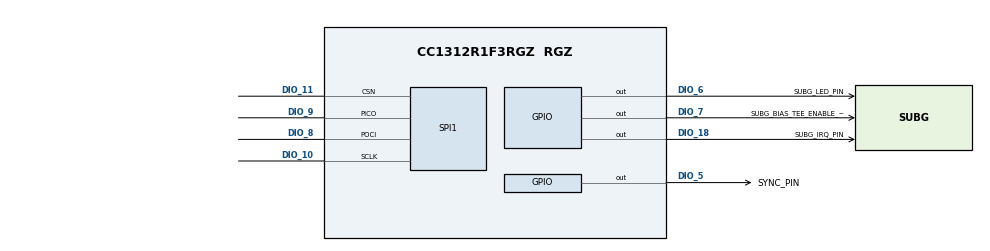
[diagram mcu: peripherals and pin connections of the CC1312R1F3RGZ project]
/**
 * @cliArgs --device "CC1312R1F3RGZ" --part "Default" --package "RGZ" --rtos "freertos" --product "simplelink_cc13xx_cc26xx_sdk@8.30.01.01"
 * @versions {"tool":"1.23.1+4034"}
 */

/**
 * Import the modules used in this configuration.
 */
const CCFG     = scripting.addModule("/ti/devices/CCFG");
const custom   = scripting.addModule("/ti/devices/radioconfig/custom");
const rfdesign = scripting.addModule("/ti/devices/radioconfig/rfdesign");
const Board    = scripting.addModule("/ti/drivers/Board");
const DMA      = scripting.addModule("/ti/drivers/DMA");
const GPIO     = scripting.addModule("/ti/drivers/GPIO");
const GPIO1    = GPIO.addInstance();
const GPIO2    = GPIO.addInstance();
const GPIO3    = GPIO.addInstance();
const GPIO4    = GPIO.addInstance();
const RF       = scripting.addModule("/ti/drivers/RF");
const SPI      = scripting.addModule("/ti/drivers/SPI", {}, false);
const SPI1     = SPI.addInstance();

/**
 * Write custom configuration values to the imported modules.
 */
CCFG.enableBootloader         = true;
CCFG.enableBootloaderBackdoor = true;
CCFG.dioBootloaderBackdoor    = 5;
CCFG.xoscCapArray             = true;
// -3 steps: CC1312 crystal on the RP2040's. ti_devices_config.c also enables the linear delta by hand.
CCFG.xoscCapArrayDelta        = 0xFD;
CCFG.ccfgTemplate.$name       = "ti_devices_CCFG_CCFGCC26XXTemplate0";

custom.prop8                                       = ["custom868"];
custom.radioConfigcustom868.$name                  = "ti_devices_radioconfig_settings_prop0";
custom.radioConfigcustom868.symbolRate             = 1000.000;
custom.radioConfigcustom868.deviation              = 350.0;
custom.radioConfigcustom868.rxFilterBw             = "2486.5";
custom.radioConfigcustom868.carrierFrequency       = 930.0000;
custom.radioConfigcustom868.codeExportConfig.$name = "ti_devices_radioconfig_code_export_param0";

Board.generateInitializationFunctions = false;

GPIO1.mode            = "Output";
GPIO1.$name           = "SUBG_LED_PIN";
GPIO1.gpioPin.$assign = "DIO_6";

GPIO2.mode               = "Output";
GPIO2.outputType         = "Open Drain";
GPIO2.pull               = "Pull Up";
GPIO2.$name              = "SUBG_IRQ_PIN";
GPIO2.initialOutputState = "High";
GPIO2.gpioPin.$assign    = "DIO_18";

GPIO3.$name           = "SYNC_PIN";
GPIO3.gpioPin.$assign = "DIO_5";

GPIO4.mode            = "Output";
GPIO4.$name           = "SUBG_BIAS_TEE_ENABLE_PIN";
GPIO4.gpioPin.$assign = "DIO_7";

RF.softwareInterruptPriority = "1";
RF.interruptPriority         = "5";

SPI1.mode                     = "Four Pin CS Active Low";
SPI1.$name                    = "COPRO_SPI";
SPI1.dmaInterruptPriority     = "5";
SPI1.sclkPinInstance.mode     = "Input";
SPI1.pociPinInstance.mode     = "Output";
SPI1.picoPinInstance.mode     = "Input";
SPI1.spi.$assign              = "SSI0";
SPI1.spi.sclkPin.$assign      = "DIO_10";
SPI1.spi.pociPin.$assign      = "DIO_8";
SPI1.spi.picoPin.$assign      = "DIO_9";
SPI1.spi.csnPin.$assign       = "DIO_11";
SPI1.spi.dmaRxChannel.$assign = "DMA_CH3";
SPI1.spi.dmaTxChannel.$assign = "DMA_CH4";
SPI1.csnPinInstance.mode      = "Input";
